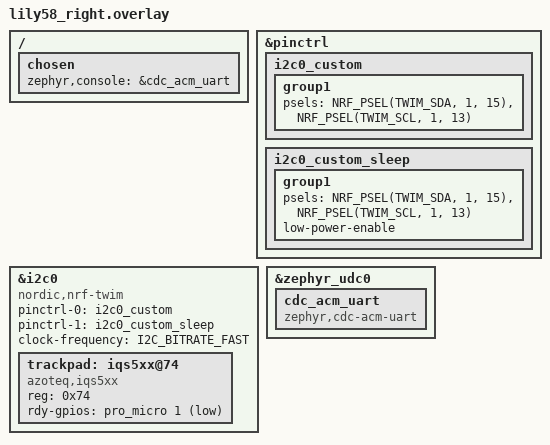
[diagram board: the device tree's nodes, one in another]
#include <dt-bindings/zmk/pointing.h>

/* 1. Hijack the SPI pins and reassign them to I2C */
&pinctrl {
    i2c0_custom: i2c0_custom {
        group1 {
            /* Route SDA to the header's 'SI' pin (P1.15) */
            psels = <NRF_PSEL(TWIM_SDA, 1, 15)>,
            /* Route SCL to the header's 'SCLK' pin (P1.13) */
                    <NRF_PSEL(TWIM_SCL, 1, 13)>;
        };
    };
    i2c0_custom_sleep: i2c0_custom_sleep {
        group1 {
            psels = <NRF_PSEL(TWIM_SDA, 1, 15)>,
                    <NRF_PSEL(TWIM_SCL, 1, 13)>;
            low-power-enable;
        };
    };
};

/* 2. Apply the custom pins to the I2C bus and define the trackpad */
&i2c0 {
    status = "okay";
    compatible = "nordic,nrf-twim";
    pinctrl-0 = <&i2c0_custom>;
    pinctrl-1 = <&i2c0_custom_sleep>;
    pinctrl-names = "default", "sleep";
    clock-frequency = <I2C_BITRATE_FAST>;

    trackpad: iqs5xx@74 {
        compatible = "azoteq,iqs5xx";
        status = "okay";
        reg = <0x74>;
        /* Route RDY to the header's 'SCS' pin (Pro Micro 1) */
        rdy-gpios = <&pro_micro 1 (GPIO_ACTIVE_LOW | GPIO_PULL_UP)>; 
    };
};
/ {
    chosen {
        zephyr,console = &cdc_acm_uart;
    };
};

&zephyr_udc0 {
    cdc_acm_uart: cdc_acm_uart {
        compatible = "zephyr,cdc-acm-uart";
    };
};
